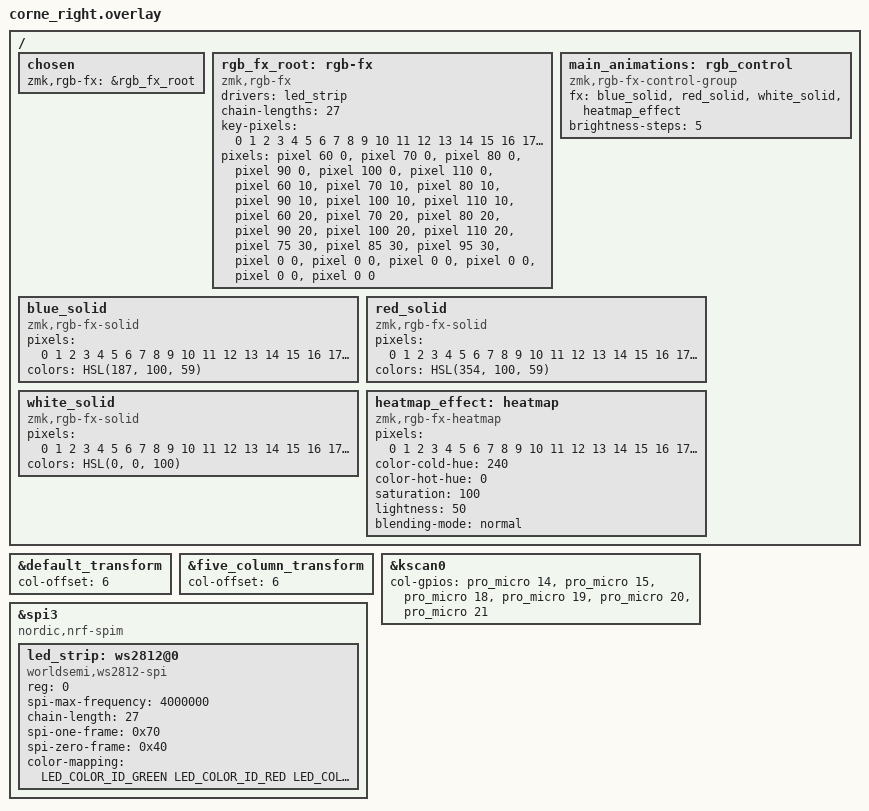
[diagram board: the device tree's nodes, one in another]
/*
 * Copyright (c) 2020 Pete Johanson
 *
 * SPDX-License-Identifier: MIT
 */

#include "corne.dtsi"
#include <dt-bindings/led/led.h>
#include <dt-bindings/zmk/rgb_fx.h>
//#include <zephyr/drivers/led_strip.h>
#include <rgb_fx.dtsi>

&default_transform {
    col-offset = <6>;
};

&five_column_transform {
    col-offset = <6>;
};

&kscan0 {
    col-gpios
        = <&pro_micro 14 GPIO_ACTIVE_HIGH>
        , <&pro_micro 15 GPIO_ACTIVE_HIGH>
        , <&pro_micro 18 GPIO_ACTIVE_HIGH>
        , <&pro_micro 19 GPIO_ACTIVE_HIGH>
        , <&pro_micro 20 GPIO_ACTIVE_HIGH>
        , <&pro_micro 21 GPIO_ACTIVE_HIGH>
        ;
};
&spi3 {
    compatible = "nordic,nrf-spim";
    status = "okay";
    
    led_strip: ws2812@0 {
        compatible = "worldsemi,ws2812-spi";
        reg = <0>;
        spi-max-frequency = <4000000>;
        chain-length = <27>;
        spi-one-frame = <0x70>;
        spi-zero-frame = <0x40>;
        color-mapping = <LED_COLOR_ID_GREEN LED_COLOR_ID_RED LED_COLOR_ID_BLUE>;
    };
};

/ {
    chosen {
        zmk,rgb-fx = &rgb_fx_root;
    };

    rgb_fx_root: rgb-fx {
        compatible = "zmk,rgb-fx";
        drivers = <&led_strip>;
        chain-lengths = <27>;
        
        // Map right half keys (positions 21-41) to LOCAL LED indices 0-20
        // The right half sees keys 21-41, but we map them to local pixels 0-20
        key-pixels = <
            0 1 2 3 4 5       // Keys 21-26 map to local pixels 0-5
            6 7 8 9 10 11     // Keys 27-32 map to local pixels 6-11
            12 13 14 15 16 17 // Keys 33-38 map to local pixels 12-17
            18 19 20          // Keys 39-41 map to local pixels 18-20
        >;
        
        // Define pixel positions (mirror of left side)
        pixels
            = <&pixel 60 0>, <&pixel 70 0>, <&pixel 80 0>, <&pixel 90 0>, <&pixel 100 0>, <&pixel 110 0>     // Top row
            , <&pixel 60 10>, <&pixel 70 10>, <&pixel 80 10>, <&pixel 90 10>, <&pixel 100 10>, <&pixel 110 10>  // Middle row
            , <&pixel 60 20>, <&pixel 70 20>, <&pixel 80 20>, <&pixel 90 20>, <&pixel 100 20>, <&pixel 110 20>  // Bottom row
            , <&pixel 75 30>, <&pixel 85 30>, <&pixel 95 30>  // Thumbs
            , <&pixel 0 0>, <&pixel 0 0>, <&pixel 0 0>, <&pixel 0 0>, <&pixel 0 0>, <&pixel 0 0>  // Extra LEDs
        ;
    };
    
    // Animation control group
    main_animations: rgb_control {
        compatible = "zmk,rgb-fx-control-group";
        
        fx = <&blue_solid &red_solid &white_solid &heatmap_effect>;
        brightness-steps = <5>;
    };
    
    // Define your effects
    blue_solid: blue_solid {
        compatible = "zmk,rgb-fx-solid";
        pixels = <0 1 2 3 4 5 6 7 8 9 10 11 12 13 14 15 16 17 18 19 20>;
        colors = <HSL(187, 100, 59)>;
    };
    
    red_solid: red_solid {
        compatible = "zmk,rgb-fx-solid";
        pixels = <0 1 2 3 4 5 6 7 8 9 10 11 12 13 14 15 16 17 18 19 20>;
        colors = <HSL(354, 100, 59)>;
    };
    
    white_solid: white_solid {
        compatible = "zmk,rgb-fx-solid";
        pixels = <0 1 2 3 4 5 6 7 8 9 10 11 12 13 14 15 16 17 18 19 20>;
        colors = <HSL(0, 0, 100)>;
    };
    
    heatmap_effect: heatmap {
        compatible = "zmk,rgb-fx-heatmap";
        pixels = <0 1 2 3 4 5 6 7 8 9 10 11 12 13 14 15 16 17 18 19 20>;
        color-cold-hue = <240>;
        color-hot-hue = <0>;
        saturation = <100>;
        lightness = <50>;
        blending-mode = "normal";
    };
};
